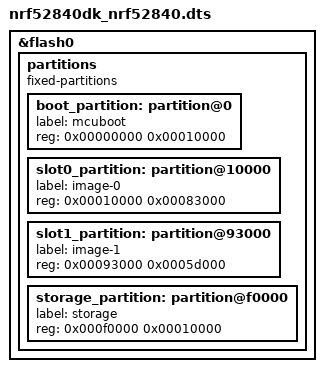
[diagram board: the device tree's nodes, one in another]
/*
 * Copyright (c) 2025 Nordic Semiconductor ASA
 *
 * SPDX-License-Identifier: LicenseRef-Nordic-5-Clause
 */

/delete-node/ &boot_partition;
/delete-node/ &slot0_partition;
/delete-node/ &slot1_partition;
/delete-node/ &storage_partition;

&flash0 {
	partitions {
		compatible = "fixed-partitions";
		#address-cells = <1>;
		#size-cells = <1>;

		boot_partition: partition@0 {
			label = "mcuboot";
			reg = <0x00000000 0x00010000>;
		};

		slot0_partition: partition@10000 {
			label = "image-0";
			reg = <0x00010000 0x00083000>;
		};

		slot1_partition: partition@93000 {
			label = "image-1";
			reg = <0x00093000 0x0005d000>;
		};

		storage_partition: partition@f0000 {
			label = "storage";
			reg = <0x000f0000 0x00010000>;
		};
	};
};
